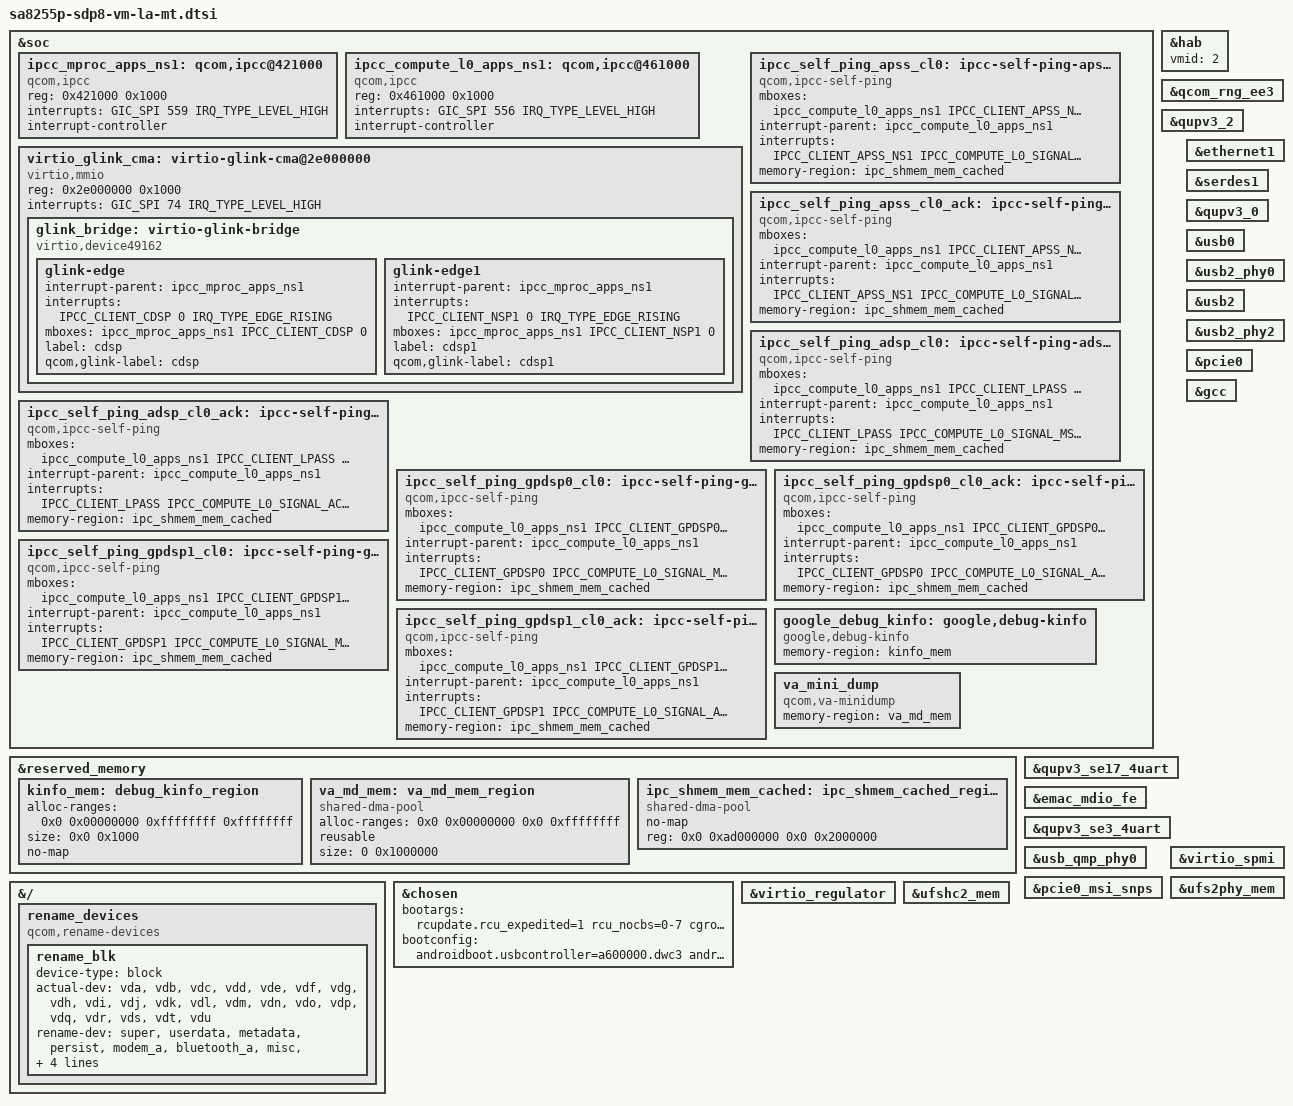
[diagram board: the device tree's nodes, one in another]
// SPDX-License-Identifier: BSD-3-Clause
/*
 * Copyright (c) Qualcomm Technologies, Inc. and/or its subsidiaries.
 */

#include <dt-bindings/mailbox/qcom-ipcc.h>

&soc {
	ipcc_mproc_apps_ns1: qcom,ipcc@421000 {
		compatible = "qcom,ipcc";
		reg = <0x421000 0x1000>;
		interrupts = <GIC_SPI 559 IRQ_TYPE_LEVEL_HIGH>;
		interrupt-controller;
		#interrupt-cells = <3>;
		#mbox-cells = <2>;
	};

	ipcc_compute_l0_apps_ns1: qcom,ipcc@461000 {
		compatible = "qcom,ipcc";
		reg = <0x461000 0x1000>;
		interrupts = <GIC_SPI 556 IRQ_TYPE_LEVEL_HIGH>;
		interrupt-controller;
		#interrupt-cells = <3>;
		#mbox-cells = <2>;
		status = "ok";
	};

	virtio_glink_cma: virtio-glink-cma@2e000000 {
		compatible = "virtio,mmio";
		reg = <0x2e000000 0x1000>;
		interrupts = <GIC_SPI 74 IRQ_TYPE_LEVEL_HIGH>;

		glink_bridge: virtio-glink-bridge {
			compatible = "virtio,device49162"; /* VIRTIO_ID: 0xC00A */

			glink-edge {
				interrupt-parent = <&ipcc_mproc_apps_ns1>;
				interrupts = <IPCC_CLIENT_CDSP 0 IRQ_TYPE_EDGE_RISING>;
				mboxes = <&ipcc_mproc_apps_ns1 IPCC_CLIENT_CDSP 0>;
				label = "cdsp";
				qcom,glink-label = "cdsp";
			};

			glink-edge1 {
				interrupt-parent = <&ipcc_mproc_apps_ns1>;
				interrupts = <IPCC_CLIENT_NSP1 0 IRQ_TYPE_EDGE_RISING>;
				mboxes = <&ipcc_mproc_apps_ns1 IPCC_CLIENT_NSP1 0>;
				label = "cdsp1";
				qcom,glink-label = "cdsp1";
			};
		};
	};
};

&reserved_memory {
	kinfo_mem: debug_kinfo_region {
		alloc-ranges = <0x0 0x00000000 0xffffffff 0xffffffff>;
		size = <0x0 0x1000>;
		no-map;
	};

	va_md_mem: va_md_mem_region {
		compatible = "shared-dma-pool";
		alloc-ranges = <0x0 0x00000000 0x0 0xffffffff>;
		reusable;
		size = <0 0x1000000>;
	};
};

&{/} {
	rename_devices: rename_devices {
		compatible = "qcom,rename-devices";
		rename_blk: rename_blk {
			device-type = "block";
			actual-dev = "vda", "vdb", "vdc",
					"vdd", "vde", "vdf",
					"vdg", "vdh", "vdi",
					"vdj", "vdk", "vdl",
					"vdm", "vdn", "vdo",
					"vdp", "vdq", "vdr",
					"vds", "vdt", "vdu";
			rename-dev = "super", "userdata", "metadata",
					"persist", "modem_a","bluetooth_a",
					"misc", "vbmeta_a", "vbmeta_b",
					"boot_a", "dtbo_a", "dsp_a",
					"modem_b", "bluetooth_b", "boot_b",
					"dtbo_b", "dsp_b", "vendor_boot_b",
					"vendor_boot_a", "init_boot_b", "init_boot_a";
		};
	};
};

&chosen {
	bootargs ="rcupdate.rcu_expedited=1 rcu_nocbs=0-7 cgroup.memory=nokmem,nosocket kpti=0 ufshcd-core.use_mcq_mode=n qcom_dma_heaps.enable_bitstream_contig_heap=y arm64.nopauth kasan=off msm_    show_resume_irq.debug_mask=1 fw_devlink.strict=1";
	bootconfig = "androidboot.usbcontroller=a600000.dwc3 androidboot.fstab_suffix=gen4.8255.qcom androidboot.dtbo_idx=20";
};

&hab {
	vmid = <2>;
};

&qcom_rng_ee3 {
	status = "ok";
};

&qupv3_2 {
	status = "ok";
};

&qupv3_se17_4uart {
	status = "ok";
};

&ethernet1 {
	status = "ok";
};

&serdes1 {
	status = "ok";
};

&emac_mdio_fe {
	status = "ok";
};

&qupv3_0 {
	status = "ok";
};

&qupv3_se3_4uart {
	status = "ok";
};

&usb0 {
	status = "ok";
};

&usb2_phy0 {
	status = "ok";
};

&usb_qmp_phy0 {
	status = "ok";
};

&usb2 {
	status = "ok";
};

&usb2_phy2 {
	status = "ok";
};

&pcie0 {
	status = "ok";
};

&pcie0_msi_snps {
	status = "ok";
};

&gcc {
	status = "ok";
};

&virtio_regulator {
	status = "ok";
};

&virtio_spmi {
	status = "ok";
};

&qcom_rng_ee3 {
	status = "ok";
};
&ufs2phy_mem {
	status = "ok";
};

&ufshc2_mem {
	status = "ok";
};

&reserved_memory {
	ipc_shmem_mem_cached: ipc_shmem_cached_region {
		compatible = "shared-dma-pool";
		no-map;
		reg = <0x0 0xad000000 0x0 0x2000000>;
	};
};

&soc {
	ipcc_compute_l0_apps_ns1: qcom,ipcc@461000 {
		compatible = "qcom,ipcc";
		reg = <0x461000 0x1000>;
		interrupts = <GIC_SPI 556 IRQ_TYPE_LEVEL_HIGH>;
		interrupt-controller;
		#interrupt-cells = <3>;
		#mbox-cells = <2>;
		status = "ok";
	};

	ipcc_self_ping_apss_cl0: ipcc-self-ping-apss_cl0 {
		compatible = "qcom,ipcc-self-ping";
		mboxes = <&ipcc_compute_l0_apps_ns1 IPCC_CLIENT_APSS_NS1
				IPCC_COMPUTE_L0_SIGNAL_MSG>;
		interrupt-parent = <&ipcc_compute_l0_apps_ns1>;
		interrupts = <IPCC_CLIENT_APSS_NS1
				IPCC_COMPUTE_L0_SIGNAL_MSG
				IRQ_TYPE_EDGE_RISING>;
		memory-region = <&ipc_shmem_mem_cached>;
	};

	ipcc_self_ping_apss_cl0_ack: ipcc-self-ping-apss_cl0_ack {
		compatible = "qcom,ipcc-self-ping";
		mboxes = <&ipcc_compute_l0_apps_ns1 IPCC_CLIENT_APSS_NS1
				IPCC_COMPUTE_L0_SIGNAL_ACK>;
		interrupt-parent = <&ipcc_compute_l0_apps_ns1>;
		interrupts = <IPCC_CLIENT_APSS_NS1
				IPCC_COMPUTE_L0_SIGNAL_ACK
				IRQ_TYPE_EDGE_RISING>;
		memory-region = <&ipc_shmem_mem_cached>;
	};

	ipcc_self_ping_adsp_cl0: ipcc-self-ping-adsp_cl0 {
		compatible = "qcom,ipcc-self-ping";
		mboxes = <&ipcc_compute_l0_apps_ns1 IPCC_CLIENT_LPASS
				IPCC_COMPUTE_L0_SIGNAL_MSG>;
		interrupt-parent = <&ipcc_compute_l0_apps_ns1>;
		interrupts = <IPCC_CLIENT_LPASS
				IPCC_COMPUTE_L0_SIGNAL_MSG
				IRQ_TYPE_EDGE_RISING>;
		memory-region = <&ipc_shmem_mem_cached>;
	};

	ipcc_self_ping_adsp_cl0_ack: ipcc-self-ping-adsp_cl0_ack {
		compatible = "qcom,ipcc-self-ping";
		mboxes = <&ipcc_compute_l0_apps_ns1 IPCC_CLIENT_LPASS
				IPCC_COMPUTE_L0_SIGNAL_ACK>;
		interrupt-parent = <&ipcc_compute_l0_apps_ns1>;
		interrupts = <IPCC_CLIENT_LPASS
				IPCC_COMPUTE_L0_SIGNAL_ACK
				IRQ_TYPE_EDGE_RISING>;
		memory-region = <&ipc_shmem_mem_cached>;
	};

	ipcc_self_ping_gpdsp0_cl0: ipcc-self-ping-gpdsp0_cl0 {
		compatible = "qcom,ipcc-self-ping";
		mboxes = <&ipcc_compute_l0_apps_ns1 IPCC_CLIENT_GPDSP0
				IPCC_COMPUTE_L0_SIGNAL_MSG>;
		interrupt-parent = <&ipcc_compute_l0_apps_ns1>;
		interrupts = <IPCC_CLIENT_GPDSP0
				IPCC_COMPUTE_L0_SIGNAL_MSG
				IRQ_TYPE_EDGE_RISING>;
		memory-region = <&ipc_shmem_mem_cached>;
	};

	ipcc_self_ping_gpdsp0_cl0_ack: ipcc-self-ping-gpdsp0_cl0_ack {
		compatible = "qcom,ipcc-self-ping";
		mboxes = <&ipcc_compute_l0_apps_ns1 IPCC_CLIENT_GPDSP0
				IPCC_COMPUTE_L0_SIGNAL_ACK>;
		interrupt-parent = <&ipcc_compute_l0_apps_ns1>;
		interrupts = <IPCC_CLIENT_GPDSP0
				IPCC_COMPUTE_L0_SIGNAL_ACK
				IRQ_TYPE_EDGE_RISING>;
		memory-region = <&ipc_shmem_mem_cached>;
	};

	ipcc_self_ping_gpdsp1_cl0: ipcc-self-ping-gpdsp1_cl0 {
		compatible = "qcom,ipcc-self-ping";
		mboxes = <&ipcc_compute_l0_apps_ns1 IPCC_CLIENT_GPDSP1
				IPCC_COMPUTE_L0_SIGNAL_MSG>;
		interrupt-parent = <&ipcc_compute_l0_apps_ns1>;
		interrupts = <IPCC_CLIENT_GPDSP1
				IPCC_COMPUTE_L0_SIGNAL_MSG
				IRQ_TYPE_EDGE_RISING>;
		memory-region = <&ipc_shmem_mem_cached>;
	};

	ipcc_self_ping_gpdsp1_cl0_ack: ipcc-self-ping-gpdsp1_cl0_ack {
		compatible = "qcom,ipcc-self-ping";
		mboxes = <&ipcc_compute_l0_apps_ns1 IPCC_CLIENT_GPDSP1
				IPCC_COMPUTE_L0_SIGNAL_ACK>;
		interrupt-parent = <&ipcc_compute_l0_apps_ns1>;
		interrupts = <IPCC_CLIENT_GPDSP1
				IPCC_COMPUTE_L0_SIGNAL_ACK
				IRQ_TYPE_EDGE_RISING>;
		memory-region = <&ipc_shmem_mem_cached>;
	};

};

&soc {
	google_debug_kinfo: google,debug-kinfo {
		compatible = "google,debug-kinfo";
		memory-region = <&kinfo_mem>;
	};

	va_mini_dump: va_mini_dump {
		compatible = "qcom,va-minidump";
		memory-region = <&va_md_mem>;
	};
};
